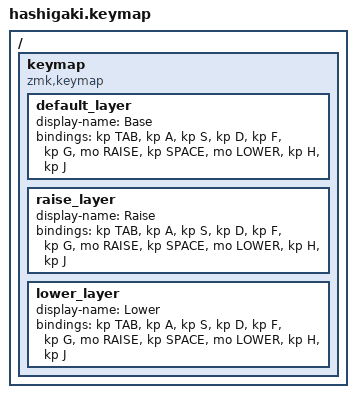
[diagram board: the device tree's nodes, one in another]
#include <behaviors.dtsi>
#include <dt-bindings/zmk/keys.h>

#define BASE 0
#define RAISE 1
#define LOWER 2

/ {
    keymap {
        compatible = "zmk,keymap";

        default_layer {
            display-name = "Base";
            bindings = <&kp TAB
                        &kp A
                        &kp S
                        &kp D
                        &kp F
                        &kp G
                        &mo RAISE
                        &kp SPACE
                        &mo LOWER
                        &kp H
                        &kp J
                        >;
        };
        raise_layer {
            display-name = "Raise";
            bindings = <&kp TAB
                        &kp A
                        &kp S
                        &kp D
                        &kp F
                        &kp G
                        &mo RAISE
                        &kp SPACE
                        &mo LOWER
                        &kp H
                        &kp J
                        >;
        };
        lower_layer {
            display-name = "Lower";
            bindings = <&kp TAB
                        &kp A
                        &kp S
                        &kp D
                        &kp F
                        &kp G
                        &mo RAISE
                        &kp SPACE
                        &mo LOWER
                        &kp H
                        &kp J
                        >;
        };
    };
};
